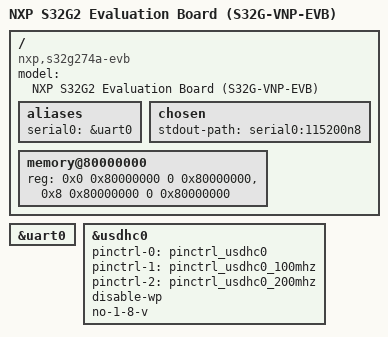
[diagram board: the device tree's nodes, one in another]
// SPDX-License-Identifier: GPL-2.0-or-later OR MIT
/*
 * Copyright (c) 2021 SUSE LLC
 * Copyright 2019-2021, 2024 NXP
 */

/dts-v1/;

#include "s32g2.dtsi"
#include "s32gxxxa-evb.dtsi"

/ {
	model = "NXP S32G2 Evaluation Board (S32G-VNP-EVB)";
	compatible = "nxp,s32g274a-evb", "nxp,s32g2";

	aliases {
		serial0 = &uart0;
	};

	chosen {
		stdout-path = "serial0:115200n8";
	};

	/* 4GiB RAM */
	memory@80000000 {
		device_type = "memory";
		reg = <0x0 0x80000000 0 0x80000000>,
		      <0x8 0x80000000 0 0x80000000>;
	};
};

/* UART (J58) to Micro USB port */
&uart0 {
	status = "okay";
};

&usdhc0 {
	pinctrl-names = "default", "state_100mhz", "state_200mhz";
	pinctrl-0 = <&pinctrl_usdhc0>;
	pinctrl-1 = <&pinctrl_usdhc0_100mhz>;
	pinctrl-2 = <&pinctrl_usdhc0_200mhz>;
	disable-wp;
	no-1-8-v;
	status = "okay";
};
